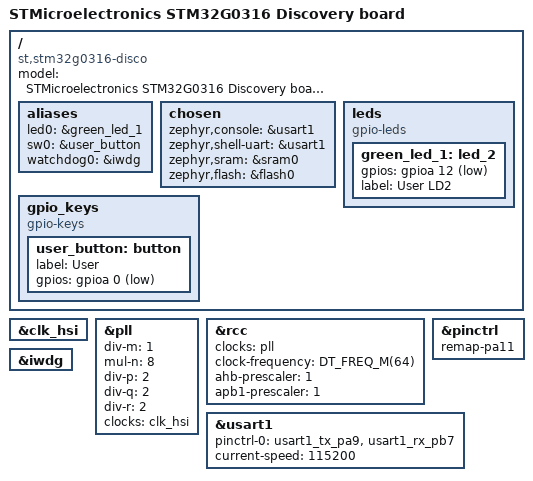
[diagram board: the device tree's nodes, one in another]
/*
 * Copyright (c) 2019 SEAL AG
 *
 * SPDX-License-Identifier: Apache-2.0
 */

/dts-v1/;
#include <st/g0/stm32g031X6.dtsi>
#include <st/g0/stm32g031j(4-6)mx-pinctrl.dtsi>

/ {
	model = "STMicroelectronics STM32G0316 Discovery board";
	compatible = "st,stm32g0316-disco";

	aliases {
		led0 = &green_led_1;
		sw0 = &user_button;
		watchdog0 = &iwdg;
	};

	chosen {
		zephyr,console = &usart1;
		zephyr,shell-uart = &usart1;
		zephyr,sram = &sram0;
		zephyr,flash = &flash0;
	};

	leds {
		compatible = "gpio-leds";
		green_led_1: led_2 {
			gpios = <&gpioa 12 GPIO_ACTIVE_LOW>;
			label = "User LD2";
		};
	};

	gpio_keys {
		compatible = "gpio-keys";
		user_button: button {
			label = "User";
			gpios = <&gpioa 0 GPIO_ACTIVE_LOW>;
		};
	};
};

&clk_hsi {
	status = "okay";
};

&pll {
	div-m = <1>;
	mul-n = <8>;
	div-p = <2>;
	div-q = <2>;
	div-r = <2>;
	clocks = <&clk_hsi>;
	status = "okay";
};

&rcc {
	clocks = <&pll>;
	clock-frequency = <DT_FREQ_M(64)>;
	ahb-prescaler = <1>;
	apb1-prescaler = <1>;
};

&pinctrl {
	remap-pa11;
};

&usart1 {
	pinctrl-0 = <&usart1_tx_pa9 &usart1_rx_pb7>;
	pinctrl-names = "default";
	current-speed = <115200>;
	status = "okay";
};

&iwdg {
	status = "okay";
};
